# TC37XPD register map
Vendor: Infineon; Series: ATVMC; File version: 100
CPU: other r0p0, little endian, MPU, FPU, vendor SysTick, 4 interrupt priority bits
Registers are 32-bit, read-write, reset 0x0 unless marked. A register's access mark holds for its fields unless they carry their own. Offsets are from the block's base; [hi:lo] are bit positions; lines under a group give offsets from that group; {n}, {i} and the like mark numbered series.

## SMU
Base 0xF0036800
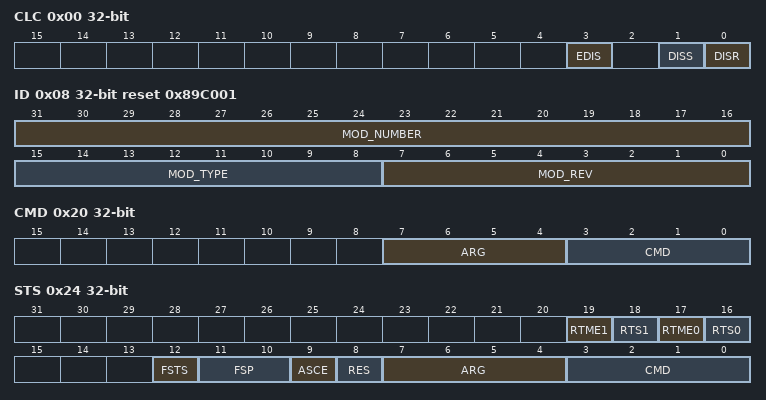
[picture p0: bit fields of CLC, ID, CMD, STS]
0x00 CLC access per field — Clock Control Register resetvalue={Application Reset:0x0}
  [3] EDIS rw — Sleep Mode Enable Control EDIS. Used to control module 8217 s sleep mode. Sleep Mode is not supported by the safety applications. During the process of entering and resuming from sleep mode the intended processing of alarm events is not guaranteed.
  [1] DISS ro — Module Disable Status Bit DISS. Bit indicates the current status of the module.
  [0] DISR rw — Module Disable Request Bit DISR. Used for enable disable control of the module.
0x08 ID ro reset 0x89C001 — Module Identification Register resetvalue={Application Reset:0x089C001}
  [31:16] MOD_NUMBER — Module Number Value MOD NUMBER. This bit field defines a module identification number. The value for the SMU module is 0089H.
  [15:8] MOD_TYPE — Module Type MOD TYPE. The bit field is set to C0H which defines the module as a 32 bit module.
  [7:0] MOD_REV — Module Revision Number MOD REV. This bit field defines the module revision number. The value of a module revision starts with 01H first revision .
0x20 CMD wo — Command Register resetvalue={Application Reset:0x0}
  [7:4] ARG — Implements the SMU core Command Interface. ARG. Argument to be used with the command. See CROSSREFERENCE for the argument encoding. Read as 0.
  [3:0] CMD — Implements the SMU core Command Interface. CMD. See CROSSREFERENCE for the command encoding. Read as 0.
0x24 STS access per field (reset mask 0xFFFFF3FF) — Status Register resetvalue={Application Reset:0x0}
  [19] RTME1 rw — Recovery Timer 1 Missed Event RTME1. See CROSSREFERENCE for the usage of this field.
  [18] RTS1 rw — Recovery Timer 1 Status RTS1. See CROSSREFERENCE for the usage of this field.
  [17] RTME0 rw — Recovery Timer 0 Missed Event RTME0. See CROSSREFERENCE for the usage of this field.
  [16] RTS0 rw — Recovery Timer 0 Status RTS0. See CROSSREFERENCE for the usage of this field.
  [12] FSTS rw — Fault State Timing Status FSTS. This bit indicates if the minimum timing duration of the FSP fault state has been reached or not. The bit is cleared by hardware when the fault state is entered.
  [11:10] FSP ro — Fault Signaling Protocol status FSP. FSP 0 FSP STS 0 input signal FSP 1 FSP STS 1 input signal This field is updated by hardware every clock cycle therefore a software clear on write is not meaningful for this field. Note When the FSP 0 and or FSP 1 is set in fault state by the SMU stdby this bitfield does not reflect the actual state of the ErrorPins. Indeed the SMU stdby sets the ErrorPins in high impedence state to indicate the presence of a fault.
  [9] ASCE rw — Alarm Status Clear Enable ASCE. This bit controls if a status flag set in an AG lt x gt register upon detection of an alarm event can be cleared by software or not. When ASCE is enabled software shall write a 1 to the bit position in AG lt x gt to clear the bit W1C . When a W1C action takes place the ASCE bit is automatically cleared to 0 by hardware and software shall set the ASCE bit again by using the SMU ASCE command.
  [8] RES rw — Result of last received command RES
  [7:4] ARG rw — Last command argument received ARG. Same encoding as ARG field of SMU CMD register
  [3:0] CMD rw — Last command received CMD. Same encoding as CMD field of SMU CMD register
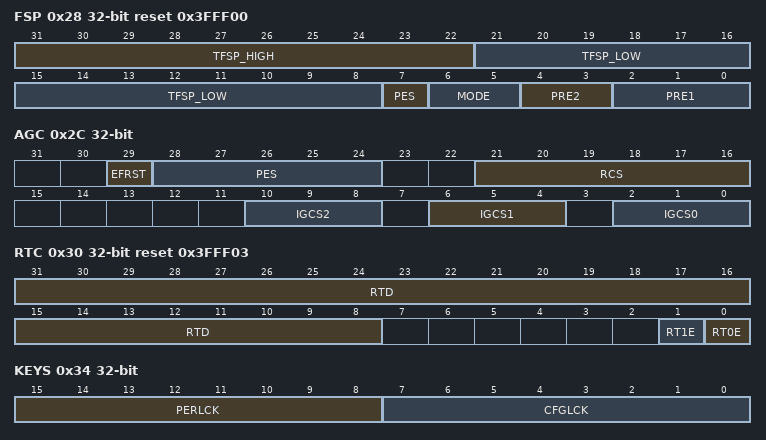
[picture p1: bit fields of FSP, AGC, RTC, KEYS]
0x28 FSP access per field reset 0x3FFF00 — Fault Signaling Protocol resetvalue={PowerOn Reset:0x3FFF00}
  [31:22] TFSP_HIGH rw — Specifies the FSP fault state duration TFSP HIGH. TFSP FS TSMU FS concatenate TFSP HIGH TFSP LOW 1 . TFSP HIGH shall be specified as a number of FSMU FS ticks. TFSP HIGH and PRE1 shall enable to configure a fault state duration of 500 ms. It is only allowed to write TFSP HIGH when the SMU is not in the Fault State and FSP is in Bi stable protocol mode.
  [21:8] TFSP_LOW ro — Specifies the FSP fault state duration TFSP LOW. TFSP FS TSMU FS concatenate TFSP HIGH TFSP LOW 1 . TFSP LOW shall be specified as a number of FSMU FS ticks. TFSP LOW is defined so that the minimum duration is greater than 250 us. It can not be changed by software.
  [7] PES rw — Port Emergency Stop PES PES. When this bit is set a Port Emergency Stop is automatically requested when an alarm event configured to start the Fault Signaling Protocol is detected.
  [6:5] MODE rw — Fault Signaling Protocol configuration MODE
  [4:3] PRE2 rw — Prescaler2 PRE2. Dividing factor to apply to the reference clock fBACK in order to generate the timing of the fault free state for the dynamic dual rail and time switching modes of the fault signaling protocol. It is only allowed to write PPRE2 when the SMU is not in the Fault State and FSP is in Bi stable protocol mode. The frequency of the divided clock called FSMU FFS is defined as follows
  [2:0] PRE1 rw — Prescaler1 PRE1. Dividing factor to apply to the reference clock fBACK. It is assumed that the maximal value for fBACK is 100 MHz with a precision of 5 . The divided clock is used as reference to generate the timing of the fault signaling protocol fault state. It is only allowed to write PRE1 when the SMU is not in the Fault State and FSP is in Bi stable protocol mode. Also it is not allowed to write to the PRE1 when at least one recovery timer is running. The frequency of the divided clock called FSMU FS is defined as follows
0x2C AGC — Alarm Global Configuration resetvalue={Application Reset:0x0}
  [29] EFRST — Enable FAULT to RUN State Transition EFRST. See CROSSREFERENCE chapter for the usage of this field.
  [28:24] PES — Port Emergency Stop PES. This field enables control of the Port Emergency Stop PES feature independently for each internal action. When an action is triggered and if the corresponding bit as defined below is set the hardware triggers automatically a port emergency stop request. Each bit of PES is allocated to an action as follows
  [21:16] RCS — CPU Reset Configuration Set RCS. Defines the output value of the CPU reset request vector when the alarm configuration flag selects the CPU Reset Configuration Set. Enables to issue an reset request to several CPUs if required. More complex reset scenarios can be handled by using software interrupts. Setting the bit n to 1 enables issuing a reset request to CPUn.
  [10:8] IGCS2 — Interrupt Generation Configuration Set 2 IGCS2. Defines the output value of the interrupt request vector when the alarm configuration flag selects the interrupt configuration set 2. Enables to issue an interrupt request to several CPUs see CROSSREFERENCE .
  [6:4] IGCS1 — Interrupt Generation Configuration Set 1 IGCS1. Defines the output value of the interrupt request vector when the alarm configuration flag selects the interrupt configuration set 1. Enables to issue an interrupt request to several CPUs see CROSSREFERENCE .
  [2:0] IGCS0 — Interrupt Generation Configuration Set 0 IGCS0. Defines the output value of the interrupt request vector when the alarm configuration flag selects the interrupt configuration set 0. Enables to issue an interrupt request to several CPUs see CROSSREFERENCE .
0x30 RTC reset 0x3FFF03 — Recovery Timer Configuration resetvalue={Application Reset:0x3FFF03}
  [31:8] RTD — Recovery Timer Duration RTD. This field specifies the maximum duration of the recovery timer. When the timer counter reaches the programmed value the internal alarm rt timeout is issued. The timer is stopped by a SMU RTStop command before the recovery timer. RTD shall be specified as a number of the FSMU FS clock ticks. It is not allowed to write to the RTD when at least one recovery timer is running.
  [1] RT1E — RT1 Enable Bit RT1E
  [0] RT0E — RT0 Enable Bit RT0E
0x34 KEYS — Key Register resetvalue={Application Reset:0x0}
  [15:8] PERLCK — Permanent Lock PERLCK. If this field is set to 0xFF no further configuration of the SMU core is possible. Refer to CROSSREFERENCE for the list of registers controlled by this field.
  [7:0] CFGLCK — Configuration Lock CFGLCK. The SMU core configuration is only possible if this field is set to 0xBC. Refer to CROSSREFERENCE for the list of registers controlled by this field.
0x38 DBG ro — Debug Register resetvalue={PowerOn Reset:0x0}
  [1:0] SSM — Running state of the SMU core State Machine SSM
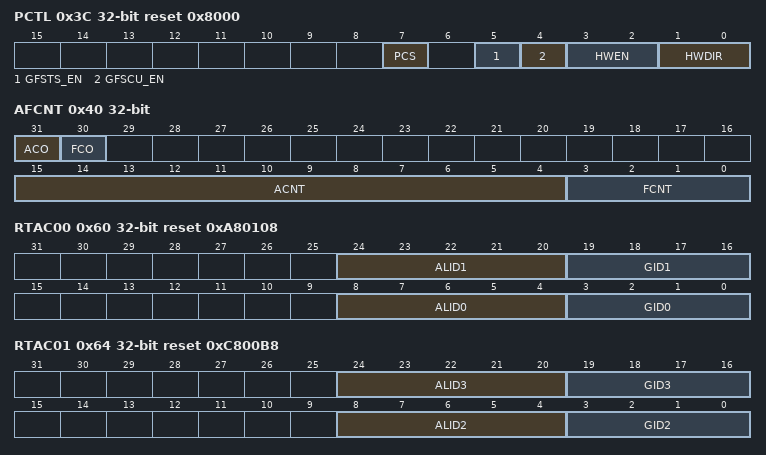
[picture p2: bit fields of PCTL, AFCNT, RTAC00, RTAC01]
0x3C PCTL reset 0x8000 — Port Control resetvalue={PowerOn Reset:0x08000}
  [7] PCS — PAD Configuration Select PCS. This bit controls the latching of the SMU core FSP Error Pin PAD configuration signals to ensure that upon an application reset or system reset the SMU core FSP Error Pin PAD configuration is not affected. This field is only reset by power on reset. Only with the first transition from 0 to 1 of this field the SMU core FSP is operational. Any further configuration change in this bit field has no effect to the hardware . The fields HWDIR HWEN and PCS shall be configured with a single software write command. Configuring each bit field separately may lead to configuration inconsistencies. Refer to CROSSREFERENCE for the overview of the SMU core FSP Error Pin connectivity. The Error Pin Pad shall be configured to the targeted function in the Port control logic before the SMU core takes over the control.
  [5] GFSTS_EN — Glitch Filter for ErrorPin SMU FSP0 to register SMU STS enable GFSTS EN
  [4] GFSCU_EN — Glitch Filter for ErrorPin SMU FSP0 to SCU enable GFSCU EN
  [3:2] HWEN — Port Enable HWEN. This bitfied directly controls the value of the FSP EN output signal. When set to 11b the port output is directly driven by SMU core FSP 1 0 . Also refer to the General Purpose I O Ports chapter for the HW EN signal specification.
  [1:0] HWDIR — Port Direction. HWDIR. This bitfield directly controls the value of the FSP DIR output signal. Also refer to the General Purpose I O Ports chapter for the HW DIR signal specification.
0x40 AFCNT ro — Alarm and Fault Counter resetvalue={PowerOn Reset:0x0}
  [31] ACO — Alarm Counter Overflow. ACO. This bit is set by hardware if the ACNT counter reached the maximum value and an increment condition is present.
  [30] FCO — Fault Counter Overflow. FCO. This bit is set by hardware if the FCNT counter reached the maximum value and an increment condition is present.
  [15:4] ACNT — Alarm Counter. ACNT. This field is incremented by hardware when the SMU core processes an internal action related to an alarm event see CROSSREFERENCE . The counter value holds if the maximum value is reached.
  [3:0] FCNT — Fault Counter. FCNT. This field is incremented by hardware when the SMU core state machine goes from the RUN state to the FAULT state see CROSSREFERENCE . The counter value holds if the maximum value is reached.
0x60 RTAC00 reset 0xA80108 — Recovery Timer 0 Alarm Configuration 0 resetvalue={Application Reset:0x0A80108}
  [24:20] ALID1 — Alarm Identifier 1. ALID1. This field specifies the alarm index related to the group index specified in GID1.
  [19:16] GID1 — Group Index 1. GID1. This field enables to specify if an alarm from this alarm group can use the recovery timer 0. The functionality of this field is described in CROSSREFERENCE .
  [8:4] ALID0 — Alarm Identifier 0. ALID0. This field specifies the alarm index related to the group index specified in GID0.
  [3:0] GID0 — Group Index 0. GID0. This field enables to specify if an alarm from this alarm group can use the recovery timer 0. The functionality of this field is described in CROSSREFERENCE .
0x64 RTAC01 reset 0xC800B8 — Recovery Timer 0 Alarm Configuration 1 resetvalue={Application Reset:0x0C800B8}
  [24:20] ALID3 — Alarm Identifier 1. ALID3. This field specifies the alarm index related to the group index specified in GID3.
  [19:16] GID3 — Group Index 3. GID3. This field enables to specify if an alarm from this alarm group can use the recovery timer 3. The functionality of this field is described in CROSSREFERENCE .
  [8:4] ALID2 — Alarm Identifier 0. ALID2. This field specifies the alarm index related to the group index specified in GID2.
  [3:0] GID2 — Group Index 2. GID2. This field enables to specify if an alarm from this alarm group can use the recovery timer 0. The functionality of this field is described in CROSSREFERENCE .
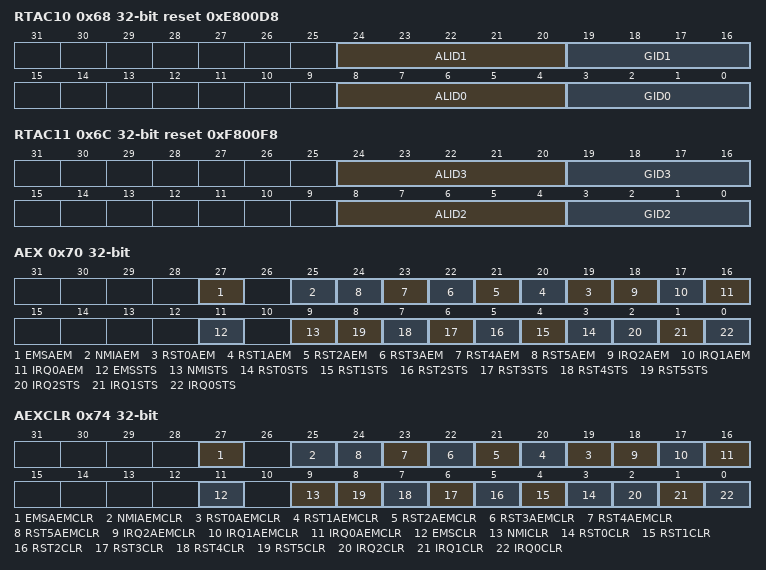
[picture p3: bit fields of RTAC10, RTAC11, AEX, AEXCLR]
0x68 RTAC10 reset 0xE800D8 — Recovery Timer 1 Alarm Configuration 0 resetvalue={Application Reset:0x0E800D8}
  [24:20] ALID1 — Alarm Identifier 1. ALID1. This field specifies the alarm index related to the group index specified in GID1.
  [19:16] GID1 — Group Index 1. GID1. This field enables to specify if an alarm from this alarm group can use the recovery timer 1. The functionality of this field is described in CROSSREFERENCE .
  [8:4] ALID0 — Alarm Identifier 0. ALID0. This field specifies the alarm index related to the group index specified in GID0.
  [3:0] GID0 — Group Index 0. GID0. This field enables to specify if an alarm from this alarm group can use the recovery timer 1. The functionality of this field is described in CROSSREFERENCE .
0x6C RTAC11 reset 0xF800F8 — Recovery Timer 1 Alarm Configuration 1 resetvalue={Application Reset:0x0F800F8}
  [24:20] ALID3 — Alarm Identifier 3. ALID3. This field specifies the alarm index related to the group index specified in GID3.
  [19:16] GID3 — Group Index 3. GID3. This field enables to specify if an alarm from this alarm group can use the recovery timer 1. The functionality of this field is described in CROSSREFERENCE .
  [8:4] ALID2 — Alarm Identifier 2. ALID2. This field specifies the alarm index related to the group index specified in GID2.
  [3:0] GID2 — Group Index 2. GID2. This field enables to specify if an alarm from this alarm group can use the recovery timer 1. The functionality of this field is described in CROSSREFERENCE .
0x70 AEX ro — Alarm Executed Status Register resetvalue={Application Reset:0x0}
  [27] EMSAEM — EMS AEM EMSAEM. This bit indicates that an alarm event is missed. That means that an alarm has occurred with configuration for EMS Request where this alarm handler was blocked because of AEX.EMSSTS. This bit can be cleared by writing with 180 1 180 to the CLR bit in the related AEXCLR register.
  [25] NMIAEM — NMI AEM NMIAEM. This bit indicates that an alarm event is missed. That means that an alarm has occurred with configuration for NMI Request where this alarm handler was blocked because of AEX.NMISTS. This bit can be cleared by writing with 180 1 180 to the CLR bit in the related AEXCLR register.
  [n+19] RST{n}AEM (n=0..5) — RST{n} AEM RST{n}AEM. This bit indicates that an alarm event is missed. That means that an alarm has occurred with configuration for CPU RST{n} Request where this alarm handler was blocked because of AEX.RST{n}STS. This bit can be cleared by writing with 180 1 180 to the CLR bit in the related AEXCLR register.
  [18] IRQ2AEM — IRQ2 AEM IRQ2AEM. This bit indicates that an alarm event is missed. That means that an alarm has occurred with configuration for IRQ2 Request where this alarm handler was blocked because of AEX.IRQ2STS. This bit can be cleared by writing with 180 1 180 to the CLR bit in the related AEXCLR register.
  [17] IRQ1AEM — IRQ1 AEM IRQ1AEM. This bit indicates that an alarm event is missed. That means that an alarm has occurred with configuration for IRQ1 Request where this alarm handler was blocked because of AEX.IRQ1STS. This bit can be cleared by writing with 180 1 180 to the CLR bit in the related AEXCLR register.
  [16] IRQ0AEM — IRQ0 AEM IRQ0AEM. This bit indicates that an alarm event is missed. That means that an alarm has occurred with configuration for IRQ0 Request where this alarm handler was blocked because of AEX.IRQ0STS. This bit can be cleared by writing with 180 1 180 to the CLR bit in the related AEXCLR register.
  [11] EMSSTS — EMS Request Status EMSSTS. This bit indicates whether a EMS request triggered by an alarm not SMU ActivatePES was serviced or not. This bit is set by the SMU core after a alarm configured for EMS is detected. This bit can be cleared by writing with 180 1 180 to the CLR bit in the related AEXCLR register.
  [9] NMISTS — NMI Request Status NMISTS. This bit indicates whether a NMI request was serviced or not. This bit is set by the SMU core after a alarm configured for NMI is detected. This bit can be cleared by writing with 180 1 180 to the CLR bit in the related AEXCLR register.
  [n+3] RST{n}STS (n=0..5) — RST{n} Request Status RST{n}STS. This bit indicates whether a RST{n} request was serviced or not. This bit is set by the SMU core after a alarm configured for RST{n} is detected. This bit can be cleared by writing with 180 1 180 to the CLR bit in the related AEXCLR register.
  [2] IRQ2STS — IRQ2 Request Status IRQ2STS. This bit indicates whether a IRQ2 request was serviced or not. This bit is set by the SMU core after a alarm configured for IRQ2 is detected. This bit can be cleared by writing with 180 1 180 to the CLR bit in the related AEXCLR register.
  [1] IRQ1STS — IRQ1 Request Status IRQ1STS. This bit indicates whether a IRQ1 request was serviced or not. This bit is set by the SMU core after a alarm configured for IRQ1 is detected. This bit can be cleared by writing with 180 1 180 to the CLR bit in the related AEXCLR register.
  [0] IRQ0STS — IRQ0 Request Status IRQ0STS. This bit indicates whether a IRQ0 request was serviced or not. This bit is set by the SMU core after a alarm configured for IRQ0 is detected. This bit can be cleared by writing with 180 1 180 to the CLR bit in the related AEXCLR register.
0x74 AEXCLR wo — Alarm Executed Status Clear Register resetvalue={Application Reset:0x0}
  [27] EMSAEMCLR — EMS AEM Status Clear EMSAEMCLR. Read always as 0.
  [25] NMIAEMCLR — NMI AEM Status Clear NMIAEMCLR. Read always as 0.
  [n+19] RST{n}AEMCLR (n=0..5) — RST{n} AEM Status Clear RST{n}AEMCLR. Read always as 0.
  [18] IRQ2AEMCLR — IRQ2 AEM Status Clear IRQ2AEMCLR. Read always as 0.
  [17] IRQ1AEMCLR — IRQ1 AEM Status Clear IRQ1AEMCLR. Read always as 0.
  [16] IRQ0AEMCLR — IRQ0 AEM Status Clear IRQ0AEMCLR. Read always as 0.
  [11] EMSCLR — EMS Request Status Clear EMSCLR. Read always as 0.
  [9] NMICLR — NMI Request Status Clear NMICLR. Read always as 0.
  [n+3] RST{n}CLR (n=0..5) — RST{n} Request Status Clear RST{n}CLR. Read always as 0.
  [2] IRQ2CLR — IRQ2 Request Status Clear IRQ2CLR. Read always as 0.
  [1] IRQ1CLR — IRQ1 Request Status Clear IRQ1CLR. Read always as 0.
  [0] IRQ0CLR — IRQ0 Request Status Clear IRQ0CLR. Read always as 0.
{0x100+4i} AGiCFj[{i}] (i=0..11) group — AGRP
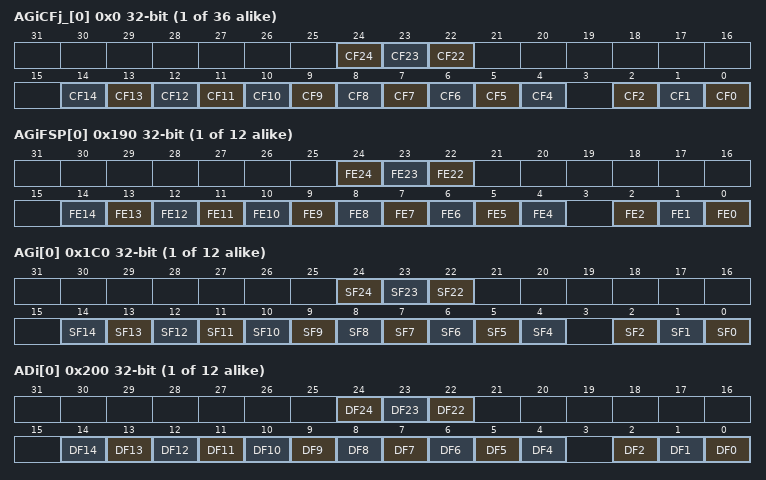
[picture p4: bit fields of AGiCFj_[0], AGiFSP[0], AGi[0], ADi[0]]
  {0x0+4j} AGiCFj_[{j}] (j=0..2) (reset mask 0xFFFC03FF) — Alarm Configuration Register resetvalue={Application Reset:0x0,Application Reset:0x1FC00,Application Reset:0x30000}
    [24] CF24 — Configuration flag x x 0 2 for alarm 31 belonging to alarm group i. CF31. The configuration flags 0 1 and 2 must be used together to define the behavior of the SMU core when a fault state is reported by the alarm n belonging to this group.
    [23] CF23 — Configuration flag x x 0 2 for alarm 31 belonging to alarm group i. CF31. The configuration flags 0 1 and 2 must be used together to define the behavior of the SMU core when a fault state is reported by the alarm n belonging to this group.
    [22] CF22 — Configuration flag x x 0 2 for alarm 31 belonging to alarm group i. CF31. The configuration flags 0 1 and 2 must be used together to define the behavior of the SMU core when a fault state is reported by the alarm n belonging to this group.
    [n] CF{n} (n=4..14) — Configuration flag x x 0 2 for alarm 31 belonging to alarm group i. CF31. The configuration flags 0 1 and 2 must be used together to define the behavior of the SMU core when a fault state is reported by the alarm n belonging to this group.
    [2] CF2 — Configuration flag x x 0 2 for alarm 31 belonging to alarm group i. CF31. The configuration flags 0 1 and 2 must be used together to define the behavior of the SMU core when a fault state is reported by the alarm n belonging to this group.
    [1] CF1 — Configuration flag x x 0 2 for alarm 31 belonging to alarm group i. CF31. The configuration flags 0 1 and 2 must be used together to define the behavior of the SMU core when a fault state is reported by the alarm n belonging to this group.
    [0] CF0 — Configuration flag x x 0 2 for alarm 31 belonging to alarm group i. CF31. The configuration flags 0 1 and 2 must be used together to define the behavior of the SMU core when a fault state is reported by the alarm n belonging to this group.
{0x190+4i} AGiFSP[{i}] (i=0..11) — SMU core FSP Configuration Register resetvalue={Application Reset:0x0,Application Reset:0x30000}
  [24] FE24 — Fault signaling configuration flag for alarm 31 belonging to alarm group i. FE31
  [23] FE23 — Fault signaling configuration flag for alarm 31 belonging to alarm group i. FE31
  [22] FE22 — Fault signaling configuration flag for alarm 31 belonging to alarm group i. FE31
  [n] FE{n} (n=4..14) — Fault signaling configuration flag for alarm 31 belonging to alarm group i. FE31
  [2] FE2 — Fault signaling configuration flag for alarm 31 belonging to alarm group i. FE31
  [1] FE1 — Fault signaling configuration flag for alarm 31 belonging to alarm group i. FE31
  [0] FE0 — Fault signaling configuration flag for alarm 31 belonging to alarm group i. FE31
{0x1C0+4i} AGi[{i}] (i=0..11) — Alarm Status Register resetvalue={Application Reset:0x0}
  [24] SF24 — Status flag for alarm 31 belonging to alarm group i. SF31
  [23] SF23 — Status flag for alarm 31 belonging to alarm group i. SF31
  [22] SF22 — Status flag for alarm 31 belonging to alarm group i. SF31
  [n] SF{n} (n=4..14) — Status flag for alarm 31 belonging to alarm group i. SF31
  [2] SF2 — Status flag for alarm 31 belonging to alarm group i. SF31
  [1] SF1 — Status flag for alarm 31 belonging to alarm group i. SF31
  [0] SF0 — Status flag for alarm 31 belonging to alarm group i. SF31
{0x200+4i} ADi[{i}] (i=0..11) ro — Alarm Debug Register resetvalue={PowerOn Reset:0x0}
  [24] DF24 — Diagnosis flag for alarm 31 belonging to alarm group i. DF31. The diagnosis registers make a snapshot of the alarm group status registers when either the executed alarm action is a reset or a state machine transition to FAULT state takes place.
  [23] DF23 — Diagnosis flag for alarm 31 belonging to alarm group i. DF31. The diagnosis registers make a snapshot of the alarm group status registers when either the executed alarm action is a reset or a state machine transition to FAULT state takes place.
  [22] DF22 — Diagnosis flag for alarm 31 belonging to alarm group i. DF31. The diagnosis registers make a snapshot of the alarm group status registers when either the executed alarm action is a reset or a state machine transition to FAULT state takes place.
  [n] DF{n} (n=4..14) — Diagnosis flag for alarm 31 belonging to alarm group i. DF31. The diagnosis registers make a snapshot of the alarm group status registers when either the executed alarm action is a reset or a state machine transition to FAULT state takes place.
  [2] DF2 — Diagnosis flag for alarm 31 belonging to alarm group i. DF31. The diagnosis registers make a snapshot of the alarm group status registers when either the executed alarm action is a reset or a state machine transition to FAULT state takes place.
  [1] DF1 — Diagnosis flag for alarm 31 belonging to alarm group i. DF31. The diagnosis registers make a snapshot of the alarm group status registers when either the executed alarm action is a reset or a state machine transition to FAULT state takes place.
  [0] DF0 — Diagnosis flag for alarm 31 belonging to alarm group i. DF31. The diagnosis registers make a snapshot of the alarm group status registers when either the executed alarm action is a reset or a state machine transition to FAULT state takes place.
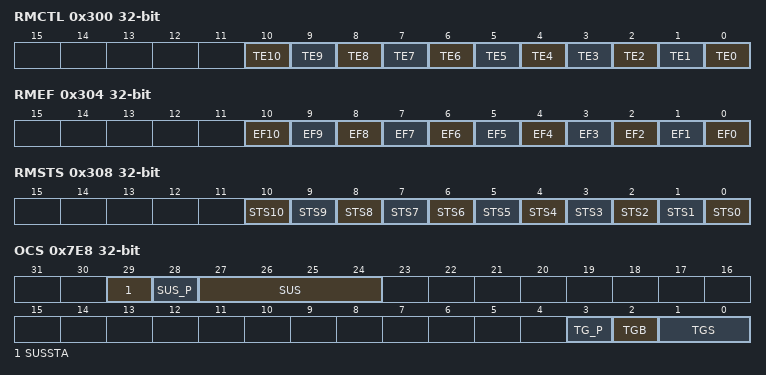
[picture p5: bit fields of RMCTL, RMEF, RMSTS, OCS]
0x300 RMCTL — Register Monitor Control resetvalue={Application Reset:0x0}
  [n] TE{n} (n=0..10) — Test Enable. TE31. This bit controls the test of the of the register monitor safety mechanism. Setting this bit starts the selft test of the safety flip flops in the corresponding module.
0x304 RMEF — Register Monitor Error Flags resetvalue={Application Reset:0x0}
  [n] EF{n} (n=0..10) — Status flag related to the different instances of the register monitor safety mechanism. EF31. It reports a real flip flop failure in non test mode as well as an unexpected behavior in test mode. This flag can only be cleared by software a set by software has no effect
0x308 RMSTS — Register Monitor Self Test Status resetvalue={Application Reset:0x0}
  [n] STS{n} (n=0..10) — Ready flag related to the different instances of the register monitor safety mechanism. STS31. A logical 8216 1 8217 of this bit indicates that the register monitor test has been executed. This bit can only be cleared by software a set by software has no effect.
0x7E8 OCS access per field — OCDS Control and Status resetvalue={Debug Reset:0x0}
  [29] SUSSTA ro — Suspend State SUSSTA. Read as 0 must be written with 0.
  [28] SUS_P wo — SUS Write Protection SUS P. SUS is only written when SUS P is 1 otherwise unchanged. Read as 0.
  [27:24] SUS rw — OCDS Suspend Control SUS. Controls the sensitivity to the suspend signal coming from the OCDS Trigger Switch OTGS
  [3] TG_P wo — TGS TGB Write Protection TG P. TGS and TGB are only written when TG P is 1 otherwise unchanged. Read as 0.
  [2] TGB rw — OTGB0 1 Bus Select TGB
  [1:0] TGS rw — Trigger Set for OTGB0 1 TGS
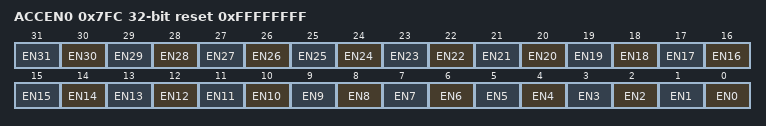
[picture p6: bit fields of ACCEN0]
0x7FC ACCEN0 reset 0xFFFFFFFF — SMU core Access Enable Register 0 resetvalue={Application Reset:0x0FFFFFFFF}
  [n] EN{n} (n=0..31) — Access Enable for Master TAG ID 31 EN31. This bit enables write access to the module kernel addresses for transactions with the Master TAG ID y
